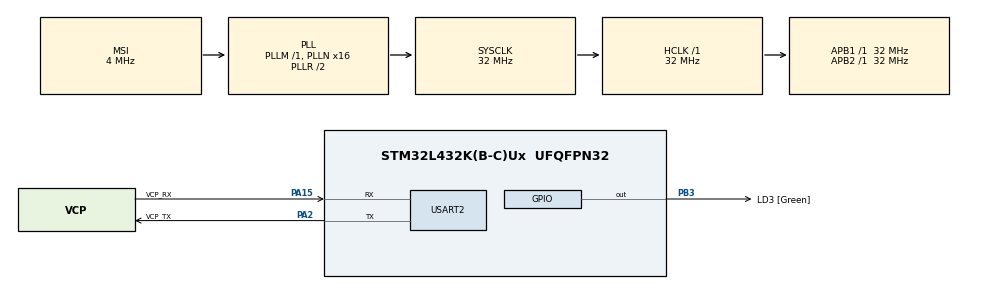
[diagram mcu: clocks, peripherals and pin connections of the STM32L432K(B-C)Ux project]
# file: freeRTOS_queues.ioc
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Mcu.Family=STM32L4
RCC.MSI_VALUE=4000000
PA14\ (JTCK-SWCLK).Mode=Serial_Wire
FREERTOS.Queues01=FIFO,16,struct data,0,Dynamic,NULL,NULL;delayPipe,4,struct delaystruct,0,Dynamic,NULL,NULL
VP_SYS_VS_tim6.Mode=TIM6
RCC.CortexFreq_Value=32000000
FREERTOS.Tasks01=Producer1,24,128,ProducerTask,Default,(void*)1,Dynamic,NULL,NULL;Producer2,24,128,ProducerTask,Default,(void*)2,Dynamic,NULL,NULL;Producer3,24,128,ProducerTask,Default,(void*)3,Dynamic,NULL,NULL;Monitor,40,256,MonitorTask,Default,NULL,Dynamic,NULL,NULL
NVIC.TIM6_DAC_IRQn=true\:0\:0\:false\:false\:true\:false\:false\:true
PA0.GPIO_Label=MCO [High speed clock in]
PC15-OSC32_OUT\ (PC15).Signal=RCC_OSC32_OUT
PA15\ (JTDI).Signal=USART2_RX
PB3\ (JTDO-TRACESWO).GPIO_Label=LD3 [Green]
PA14\ (JTCK-SWCLK).GPIO_Label=SWCLK
PC15-OSC32_OUT\ (PC15).Mode=LSE-External-Oscillator
NVIC.USART2_IRQn=true\:1\:0\:true\:true\:true\:1\:false\:true\:true
RCC.SYSCLKSource=RCC_SYSCLKSOURCE_PLLCLK
ProjectManager.StackSize=0x400
PB3\ (JTDO-TRACESWO).Signal=GPIO_Output
PC14-OSC32_IN\ (PC14).Mode=LSE-External-Oscillator
VP_FREERTOS_VS_CMSIS_V2.Mode=CMSIS_V2
PA14\ (JTCK-SWCLK).Signal=SYS_JTCK-SWCLK
RCC.HSI16_VALUE=16000000
PA15\ (JTDI).Mode=Asynchronous
ProjectManager.TargetToolchain=STM32CubeIDE
RCC.HCLKFreq_Value=32000000
RCC.APB2TimFreq_Value=32000000
RCC.AHBFreq_Value=32000000
RCC.HSE_VALUE=8000000
board=NUCLEO-L432KC
USART2.VirtualMode-Asynchronous=VM_ASYNC
RCC.VCOOutputFreq_Value=64000000
RCC.PLLMUL=RCC_PLLMUL_4
RCC.APB2Freq_Value=32000000
PA13\ (JTMS-SWDIO).GPIO_Label=SWDIO
PA0.Mode=HSE-External-Clock-Source-for-LittleOrca
PA15\ (JTDI).GPIO_Label=VCP_RX
Mcu.Name=STM32L432K(B-C)Ux
FREERTOS.configTOTAL_HEAP_SIZE=6000
PA2.Signal=USART2_TX
PA0.Signal=RCC_CK_IN
PA13\ (JTMS-SWDIO).Mode=Serial_Wire
RCC.SYSCLKFreq_VALUE=32000000
Mcu.Package=UFQFPN32
NVIC.TimeBase=TIM6_DAC_IRQn
PC14-OSC32_IN\ (PC14).Signal=RCC_OSC32_IN
PA2.GPIO_Label=VCP_TX
NVIC.TimeBaseIP=TIM6
ProjectManager.HeapSize=0x200
RCC.HSI_VALUE=16000000
NVIC.PriorityGroup=NVIC_PRIORITYGROUP_4
RCC.PLLN=16
RCC.APB1TimFreq_Value=32000000
PA2.Mode=Asynchronous
PA13\ (JTMS-SWDIO).Signal=SYS_JTMS-SWDIO
RCC.APB1Freq_Value=32000000
RCC.HSI48_VALUE=48000000

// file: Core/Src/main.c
/* USER CODE BEGIN Header */
/**
  ******************************************************************************
  * @file           : main.c
  * @brief          : Main program body
  ******************************************************************************
  * @attention
  *
  * <h2><center>&copy; Copyright (c) 2021 STMicroelectronics.
  * All rights reserved.</center></h2>
  *
  * This software component is licensed by ST under BSD 3-Clause license,
  * the "License"; You may not use this file except in compliance with the
  * License. You may obtain a copy of the License at:
  *                        opensource.org/licenses/BSD-3-Clause
  *
  ******************************************************************************
  */
/* USER CODE END Header */
#include "main.h"
#include "cmsis_os.h"

/* USER CODE BEGIN Includes */
#include "stdio.h"
#include "retarget.h"
#include "string.h"
/* USER CODE END Includes */

/* USER CODE BEGIN PTD */
struct data{
	char up[11], down[11];
};

struct delaystruct{
	uint16_t time;
	uint8_t producer;
};
/* USER CODE END PTD */

/* USER CODE BEGIN PD */
#define TRUE 1
#define FALSE 0

/* USER CODE END PD */

/* USER CODE BEGIN PM */
_Bool full = FALSE;
uint32_t plus = 0, minus = -1;
struct data put;

//input buffer
char input[20] = {0};
char* input_pointer = input;

/* USER CODE END PM */

UART_HandleTypeDef huart2;

/* Definitions for Producer1 */
osThreadId_t Producer1Handle;
const osThreadAttr_t Producer1_attributes = {
  .name = "Producer1",
  .stack_size = 128 * 4,
  .priority = (osPriority_t) osPriorityNormal,
};
/* Definitions for Producer2 */
osThreadId_t Producer2Handle;
const osThreadAttr_t Producer2_attributes = {
  .name = "Producer2",
  .stack_size = 128 * 4,
  .priority = (osPriority_t) osPriorityNormal,
};
/* Definitions for Producer3 */
osThreadId_t Producer3Handle;
const osThreadAttr_t Producer3_attributes = {
  .name = "Producer3",
  .stack_size = 128 * 4,
  .priority = (osPriority_t) osPriorityNormal,
};
/* Definitions for Monitor */
osThreadId_t MonitorHandle;
const osThreadAttr_t Monitor_attributes = {
  .name = "Monitor",
  .stack_size = 256 * 4,
  .priority = (osPriority_t) osPriorityHigh,
};
/* Definitions for FIFO */
osMessageQueueId_t FIFOHandle;
const osMessageQueueAttr_t FIFO_attributes = {
  .name = "FIFO"
};
/* Definitions for delayPipe */
osMessageQueueId_t delayPipeHandle;
const osMessageQueueAttr_t delayPipe_attributes = {
  .name = "delayPipe"
};

void SystemClock_Config(void);
static void MX_GPIO_Init(void);
static void MX_USART2_UART_Init(void);
void ProducerTask(void *argument);
void MonitorTask(void *argument);

static void MX_NVIC_Init(void);

/* USER CODE BEGIN 0 */

void RXISR(UART_HandleTypeDef *huart){
	//write UART to internal buffer for later processing
	HAL_UART_Receive(&huart2, (uint8_t*)input_pointer, 1, 1);
	input_pointer++;
}

/* USER CODE END 0 */

int main(void)
{

  /* MCU Configuration--------------------------------------------------------*/

  /* Reset of all peripherals, Initializes the Flash interface and the Systick. */
  HAL_Init();

  /* Configure the system clock */
  SystemClock_Config();

  /* Initialize all configured peripherals */
  MX_GPIO_Init();
  MX_USART2_UART_Init();

  /* Initialize interrupts */
  MX_NVIC_Init();
  /* USER CODE BEGIN 2 */
  RetargetInit(&huart2);
  /* USER CODE END 2 */

  /* Init scheduler */
  osKernelInitialize();

  /* Create the queue(s) */
  /* creation of FIFO */
  FIFOHandle = osMessageQueueNew (16, sizeof(struct data), &FIFO_attributes);

  /* creation of delayPipe */
  delayPipeHandle = osMessageQueueNew (4, sizeof(struct delaystruct), &delayPipe_attributes);

  /* Create the thread(s) */
  /* creation of Producer1 */
  Producer1Handle = osThreadNew(ProducerTask, (void*)1, &Producer1_attributes);

  /* creation of Producer2 */
  Producer2Handle = osThreadNew(ProducerTask, (void*)2, &Producer2_attributes);

  /* creation of Producer3 */
  Producer3Handle = osThreadNew(ProducerTask, (void*)3, &Producer3_attributes);

  /* creation of Monitor */
  MonitorHandle = osThreadNew(MonitorTask, NULL, &Monitor_attributes);

  /* Start scheduler */
  osKernelStart();

  /* We should never get here as control is now taken by the scheduler */
  /* Infinite loop */
  while (1)
  {

  }
}

void SystemClock_Config(void)
{
  RCC_OscInitTypeDef RCC_OscInitStruct = {0};
  RCC_ClkInitTypeDef RCC_ClkInitStruct = {0};
  RCC_PeriphCLKInitTypeDef PeriphClkInit = {0};

  /** Configure LSE Drive Capability
  */
  HAL_PWR_EnableBkUpAccess();
  __HAL_RCC_LSEDRIVE_CONFIG(RCC_LSEDRIVE_LOW);
  /** Initializes the RCC Oscillators according to the specified parameters
  * in the RCC_OscInitTypeDef structure.
  */
  RCC_OscInitStruct.OscillatorType = RCC_OSCILLATORTYPE_LSE|RCC_OSCILLATORTYPE_MSI;
  RCC_OscInitStruct.LSEState = RCC_LSE_ON;
  RCC_OscInitStruct.MSIState = RCC_MSI_ON;
  RCC_OscInitStruct.MSICalibrationValue = 0;
  RCC_OscInitStruct.MSIClockRange = RCC_MSIRANGE_6;
  RCC_OscInitStruct.PLL.PLLState = RCC_PLL_ON;
  RCC_OscInitStruct.PLL.PLLSource = RCC_PLLSOURCE_MSI;
  RCC_OscInitStruct.PLL.PLLM = 1;
  RCC_OscInitStruct.PLL.PLLN = 16;
  RCC_OscInitStruct.PLL.PLLP = RCC_PLLP_DIV7;
  RCC_OscInitStruct.PLL.PLLQ = RCC_PLLQ_DIV2;
  RCC_OscInitStruct.PLL.PLLR = RCC_PLLR_DIV2;
  if (HAL_RCC_OscConfig(&RCC_OscInitStruct) != HAL_OK)
  {
    Error_Handler();
  }
  /** Initializes the CPU, AHB and APB buses clocks
  */
  RCC_ClkInitStruct.ClockType = RCC_CLOCKTYPE_HCLK|RCC_CLOCKTYPE_SYSCLK
                              |RCC_CLOCKTYPE_PCLK1|RCC_CLOCKTYPE_PCLK2;
  RCC_ClkInitStruct.SYSCLKSource = RCC_SYSCLKSOURCE_PLLCLK;
  RCC_ClkInitStruct.AHBCLKDivider = RCC_SYSCLK_DIV1;
  RCC_ClkInitStruct.APB1CLKDivider = RCC_HCLK_DIV1;
  RCC_ClkInitStruct.APB2CLKDivider = RCC_HCLK_DIV1;

  if (HAL_RCC_ClockConfig(&RCC_ClkInitStruct, FLASH_LATENCY_1) != HAL_OK)
  {
    Error_Handler();
  }
  PeriphClkInit.PeriphClockSelection = RCC_PERIPHCLK_USART2;
  PeriphClkInit.Usart2ClockSelection = RCC_USART2CLKSOURCE_PCLK1;
  if (HAL_RCCEx_PeriphCLKConfig(&PeriphClkInit) != HAL_OK)
  {
    Error_Handler();
  }
  /** Configure the main internal regulator output voltage
  */
  if (HAL_PWREx_ControlVoltageScaling(PWR_REGULATOR_VOLTAGE_SCALE1) != HAL_OK)
  {
    Error_Handler();
  }
  /** Enable MSI Auto calibration
  */
  HAL_RCCEx_EnableMSIPLLMode();
}

/**
  * @brief NVIC Configuration.
  * @retval None
  */
static void MX_NVIC_Init(void)
{
  /* USART2_IRQn interrupt configuration */
  HAL_NVIC_SetPriority(USART2_IRQn, 1, 0);
  HAL_NVIC_EnableIRQ(USART2_IRQn);
}

static void MX_USART2_UART_Init(void)
{

  huart2.Instance = USART2;
  huart2.Init.BaudRate = 115200;
  huart2.Init.WordLength = UART_WORDLENGTH_8B;
  huart2.Init.StopBits = UART_STOPBITS_1;
  huart2.Init.Parity = UART_PARITY_NONE;
  huart2.Init.Mode = UART_MODE_TX_RX;
  huart2.Init.HwFlowCtl = UART_HWCONTROL_NONE;
  huart2.Init.OverSampling = UART_OVERSAMPLING_16;
  huart2.Init.OneBitSampling = UART_ONE_BIT_SAMPLE_DISABLE;
  huart2.AdvancedInit.AdvFeatureInit = UART_ADVFEATURE_NO_INIT;
  if (HAL_UART_Init(&huart2) != HAL_OK)
  {
    Error_Handler();
  }
  /* USER CODE BEGIN USART2_Init 2 */

  //enable Rx interrupt
  huart2.Instance->CR1 |= USART_CR1_RXNEIE;
  huart2.RxISR = &RXISR;

  /* USER CODE END USART2_Init 2 */

}

static void MX_GPIO_Init(void)
{
  GPIO_InitTypeDef GPIO_InitStruct = {0};

  /* GPIO Ports Clock Enable */
  __HAL_RCC_GPIOC_CLK_ENABLE();
  __HAL_RCC_GPIOA_CLK_ENABLE();
  __HAL_RCC_GPIOB_CLK_ENABLE();

  /*Configure GPIO pin Output Level */
  HAL_GPIO_WritePin(LD3_GPIO_Port, LD3_Pin, GPIO_PIN_RESET);

  /*Configure GPIO pin : LD3_Pin */
  GPIO_InitStruct.Pin = LD3_Pin;
  GPIO_InitStruct.Mode = GPIO_MODE_OUTPUT_PP;
  GPIO_InitStruct.Pull = GPIO_NOPULL;
  GPIO_InitStruct.Speed = GPIO_SPEED_FREQ_LOW;
  HAL_GPIO_Init(LD3_GPIO_Port, &GPIO_InitStruct);

}

void ProducerTask(void *argument)
{
  /* USER CODE BEGIN 5 */
	uint8_t delaytime = 100;
	struct delaystruct delay;

  /* Infinite loop */
  for(;;)
  {
    memset(&put, 0, sizeof(struct data));
    //change data and write to struct as string
	sprintf(put.up, "%lu", ++plus);
    sprintf(put.down, "%lu", --minus);

    //put data into Queue
    if(osMessageQueuePut(FIFOHandle, &put, 0, 0) == osOK){full = FALSE;}
    else{
    	full = TRUE;
    }
    //check if delaytime Queue has an objet
    if(osMessageQueueGet(delayPipeHandle, &delay, 0, 0) == osOK){
    	if(delay.producer != (int)argument){
    		//is wrong producer, put back into queue
    		osMessageQueuePut(delayPipeHandle, &delay, 0, 0);
    	}
    	else{
    		//set delay
    		delaytime = delay.time;
    	}
    }

	osDelay(delaytime);
  }
  /* USER CODE END 5 */
}

void MonitorTask(void *argument)
{
  /* USER CODE BEGIN MonitorTask */
  struct data get;
  int producer = 0, delaytime = 0;
  struct delaystruct delay;

  /* Infinite loop */
  for(;;)
  {
	  //get data from queue and print it
	  if(osMessageQueueGet(FIFOHandle, &get, 0, 0) == osOK){
		  printf(" plus: %s\nminus: %s\n%s", get.up, get.down, full ? "Queue full !!!\n" : "");
	  }
	  //read from UART buffer writen to by interrupt; not using scanf because it blocks for ever if nothing is read
	  if (input[0] != 0 && strchr(input, 's') != NULL){  //check if data it transfered completely
		  if(sscanf(input, "T%d %d", &producer, &delaytime) == 2){
			  if(producer > 3){
				  printf("----------------> No %d. Producer", producer);
			  }
			  else{
				  //put delay time and producer into Queue
				  delay.time = delaytime;
				  delay.producer = producer;
				  if(osMessageQueuePut(delayPipeHandle, &delay, 0, 0) != osOK) { printf("delay Pipline full!!!");}
				  printf("Producer %d delay set to %dms\n", producer, delaytime);
			  }

			  //clear input buffer
			  memset(&input, 0, 20);
			  input_pointer = input;
		  }
		  else{
			  printf("----------------> data invalid \"%s\"\n", input);
		  }
	  }
	  /*
	  //for debugging
	  printf("==================> stack high water mark: %ld\n", uxTaskGetStackHighWaterMark(MonitorHandle));
	  printf("==================> stack high water mark: %ld\n", uxTaskGetStackHighWaterMark(Producer1Handle));
	  printf("==================> stack high water mark: %ld\n", uxTaskGetStackHighWaterMark(Producer2Handle));
	  printf("==================> stack high water mark: %ld\n", uxTaskGetStackHighWaterMark(Producer3Handle));
	  */
	  osDelay(100);
  }
  /* USER CODE END MonitorTask */
}

 /**
  * @brief  Period elapsed callback in non blocking mode
  * @note   This function is called  when TIM6 interrupt took place, inside
  * HAL_TIM_IRQHandler(). It makes a direct call to HAL_IncTick() to increment
  * a global variable "uwTick" used as application time base.
  * @param  htim : TIM handle
  * @retval None
  */
void HAL_TIM_PeriodElapsedCallback(TIM_HandleTypeDef *htim)
{
  if (htim->Instance == TIM6) {
    HAL_IncTick();
  }
}

void Error_Handler(void)
{
  __disable_irq();
  while (1)
  {
  }
}

/************************ (C) COPYRIGHT STMicroelectronics *****END OF FILE****/
